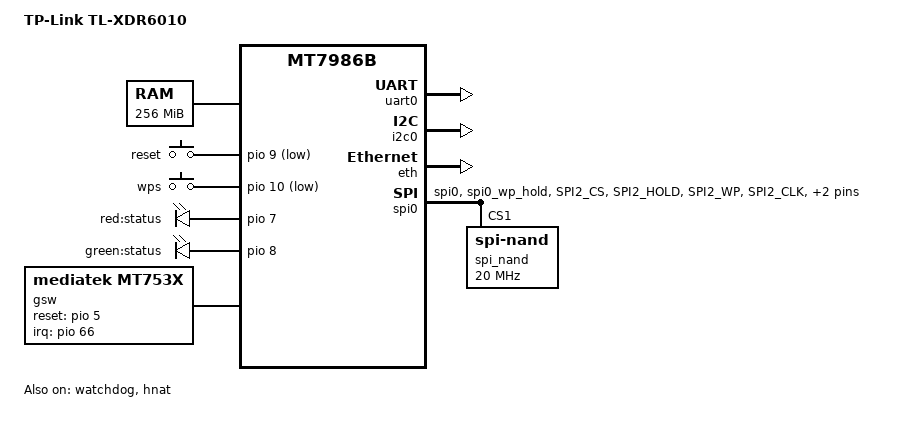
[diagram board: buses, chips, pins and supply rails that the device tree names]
/dts-v1/;
#include "mt7986b.dtsi"
#include "mt7986b-pinctrl.dtsi"
/ {
	model = "TP-Link TL-XDR6010";
	compatible = "tplink,tl-xdr6010", "mediatek,mt7986b-nor-rfb";

 	aliases {
 		serial0 = &uart0;
 		led-boot = &led_status_red;
 		led-failsafe = &led_status_red;
 		led-running = &led_status_green;
 		led-upgrade = &led_status_green;
 	};

	chosen {
		bootargs = "console=ttyS0,115200n1 loglevel=8  \
		earlycon=uart8250,mmio32,0x11002000";
	};
	
	memory {
		reg = <0 0x40000000 0 0x10000000>;
	};

    gpio-keys {
		compatible = "gpio-keys";

		reset {
 			label = "reset";
 			linux,code = <KEY_RESTART>;
 			gpios = <&pio 9 GPIO_ACTIVE_LOW>;
 		};

 		wps {
 			label = "wps";
 			linux,code = <KEY_WPS_BUTTON>;
 			gpios = <&pio 10 GPIO_ACTIVE_LOW>;
 		};
	};

	
	leds {
		compatible = "gpio-leds";

		led_status_red: status_red {
 			label = "red:status";
 			gpios = <&pio 7 GPIO_ACTIVE_HIGH>;
 		};

 		led_status_green: status_green {
 			label = "green:status";
 			gpios = <&pio 8 GPIO_ACTIVE_HIGH>;
 		};
	};

	gsw: gsw@0 {
		compatible = "mediatek,mt753x";
		mediatek,ethsys = <&ethsys>;
		#address-cells = <1>;
		#size-cells = <0>;
	};

    nmbm_spim_nand {
		compatible = "generic,nmbm";

		#address-cells = <1>;
		#size-cells = <1>;

		lower-mtd-device = <&spi_nand>;
		forced-create;

	           partitions {
			compatible = "fixed-partitions";
			#address-cells = <1>;
			#size-cells = <1>;

			partition@0 {
				label = "BL2";
				reg = <0x00000 0x0100000>;
				read-only;
			};

			partition@100000 {
				label = "u-boot-env";
				reg = <0x0100000 0x0080000>;
			};

			Factory: partition@180000 {
				label = "Factory";
				reg = <0x180000 0x0200000>;
			};

			partition@380000 {
				label = "FIP";
				reg = <0x380000 0x0200000>;
			};

			partition@580000 {
				label = "ubi";
				reg = <0x580000 0x7280000>;
			};
		};
	};
};

&uart0 {
	status = "okay";
};

&i2c0 {
	pinctrl-names = "default";
	pinctrl-0 = <&i2c_pins>;
	status = "okay";
};

&watchdog {
	status = "okay";
};

&eth {
	status = "okay";

	gmac0: mac@0 {
		compatible = "mediatek,eth-mac";
		reg = <0>;
		phy-mode = "2500base-x";

		fixed-link {
			speed = <2500>;
			full-duplex;
			pause;
		};	
	};

	gmac1: mac@1 {
		compatible = "mediatek,eth-mac";
		reg = <1>;
		phy-mode = "2500base-x";

		fixed-link {
			speed = <2500>;
			full-duplex;
			pause;
		};

	};

	mdio: mdio-bus {
		#address-cells = <1>;
		#size-cells = <0>;
	};
};

&gsw {
	mediatek,mdio = <&mdio>;
	mediatek,portmap = "lllll";
	mediatek,mdio_master_pinmux = <1>;
	reset-gpios = <&pio 5 0>;
	interrupt-parent = <&pio>;
	interrupts = <66 IRQ_TYPE_LEVEL_HIGH>;
	status = "okay";

	port5: port@5 {
		compatible = "mediatek,mt753x-port";
		reg = <5>;
		phy-mode = "sgmii";

		fixed-link {
			speed = <2500>;
			full-duplex;
		};
	};

	port6: port@6 {
		compatible = "mediatek,mt753x-port";
		reg = <6>;
		phy-mode = "sgmii";
		fixed-link {
			speed = <2500>;
			full-duplex;
		};
	};
};

&hnat {
	mtketh-wan = "eth0.2";
	mtketh-ppd = "eth0.1";
	mtketh-lan = "eth0";
	mtketh-max-gmac = <1>;
	status = "okay";
};

&spi0 {
	pinctrl-names = "default";
	pinctrl-0 = <&spi_flash_pins>;
	status = "okay";
	cs-gpios = <0>, <0>;
	spi_nand: spi_nand@0 {
		#address-cells = <1>;
		#size-cells = <1>;
		compatible = "spi-nand";
		reg = <1>;
		spi-max-frequency = <20000000>;
		spi-tx-buswidth = <4>;
		spi-rx-buswidth = <4>;
	};
};

&pio {
	spi_flash_pins: spi-flash-pins-33-to-38 {
		mux {
			function = "flash";
			groups = "spi0", "spi0_wp_hold";
		};
		conf-pu {
			pins = "SPI2_CS", "SPI2_HOLD", "SPI2_WP";
			drive-strength = <8>;
			mediatek,pull-up-adv = <0>;
		};
		conf-pd {
			pins = "SPI2_CLK", "SPI2_MOSI", "SPI2_MISO";
			drive-strength = <8>;
			mediatek,pull-down-adv = <0>;
		};
	};

	wf_2g_5g_pins: wf_2g_5g-pins {
		mux {
			function = "wifi";
			groups = "wf_2g", "wf_5g";
		};
		conf {
			pins = "WF0_HB1", "WF0_HB2", "WF0_HB3", "WF0_HB4",
			       "WF0_HB0", "WF0_HB0_B", "WF0_HB5", "WF0_HB6",
			       "WF0_HB7", "WF0_HB8", "WF0_HB9", "WF0_HB10",
			       "WF0_TOP_CLK", "WF0_TOP_DATA", "WF1_HB1",
			       "WF1_HB2", "WF1_HB3", "WF1_HB4", "WF1_HB0",
			       "WF1_HB5", "WF1_HB6", "WF1_HB7", "WF1_HB8",
			       "WF1_TOP_CLK", "WF1_TOP_DATA";
			drive-strength = <MTK_DRIVE_4mA>;
		};
	};

	wf_dbdc_pins: wf_dbdc-pins {
		mux {
			function = "wifi";
			groups = "wf_dbdc";
		};
		conf {
			pins = "WF0_HB1", "WF0_HB2", "WF0_HB3", "WF0_HB4",
			       "WF0_HB0", "WF0_HB0_B", "WF0_HB5", "WF0_HB6",
			       "WF0_HB7", "WF0_HB8", "WF0_HB9", "WF0_HB10",
			       "WF0_TOP_CLK", "WF0_TOP_DATA", "WF1_HB1",
			       "WF1_HB2", "WF1_HB3", "WF1_HB4", "WF1_HB0",
			       "WF1_HB5", "WF1_HB6", "WF1_HB7", "WF1_HB8",
			       "WF1_TOP_CLK", "WF1_TOP_DATA";
			drive-strength = <MTK_DRIVE_4mA>;
		};
	};
};
